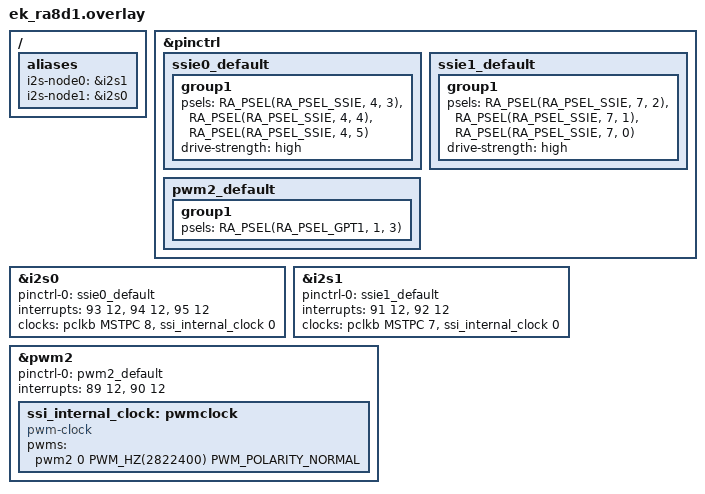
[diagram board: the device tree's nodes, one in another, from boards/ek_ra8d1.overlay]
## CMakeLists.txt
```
# SPDX-License-Identifier: Apache-2.0

cmake_minimum_required(VERSION 3.28.0)

find_package(Zephyr REQUIRED HINTS $ENV{ZEPHYR_BASE})
project(i2s_speed)

FILE(GLOB app_sources src/*.c)
target_sources(app PRIVATE ${app_sources})
```

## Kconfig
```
#
# Copyright (c) 2021, NXP
#
# SPDX-License-Identifier: Apache-2.0
#

mainmenu "I2S Speed Test"

source "Kconfig.zephyr"

config I2S_TEST_SEPARATE_DEVICES
	bool "Use two separate I2S ports for loopback"
	help
	  Use separate I2S ports for transmit and receive.

config I2S_TEST_USE_I2S_DIR_BOTH
	bool "Use I2S_DIR_BOTH value to perform RX/TX transfers"
	default y if DT_HAS_NORDIC_NRF_I2S_ENABLED || DT_HAS_NORDIC_NRF_TDM_ENABLED
	help
	  Use the I2S_DIR_BOTH enumeration value to trigger commands in test
	  cases involving both reception and transmission. Use of this option
	  is essential for devices that cannot independently start and stop
	  the RX and TX streams.

config I2S_TEST_USE_GPIO_LOOPBACK
	bool "Use GPIO loopback"
	default y if DT_HAS_NORDIC_NRF_I2S_ENABLED || DT_HAS_NORDIC_NRF_TDM_ENABLED
	help
	  Use wiring between the data-out and data-in pins for looping back
	  data. This option is intended to be used for devices that do not
	  provide the internal loopback functionality.

config I2S_TEST_ALLOWED_DATA_OFFSET
	int "Allowed offset in received data"
	default 2 if DT_HAS_NORDIC_NRF_I2S_ENABLED || DT_HAS_NORDIC_NRF_TDM_ENABLED
	default 0
	help
	  Maximum allowed offset between sent and received samples. Non-zero
	  value of this option may be needed when GPIO loopback is used.

config I2S_TEST_ALLOW_VARIABLE_OFFSET
	bool "Recalculate the data offset on every block read"
	help
	  If the data offset is not consistent between reads because of
	  timing variations in the hardware, enable this option to
	  always recalculate the offset.

config I2S_TEST_USE_32_SAMPLES_PER_BLOCK
	bool "Use 32 samples per block"
	help
	  When set to 'y', the test will use 32 samples per block
	  instead of the default 64 samples per block. This option
	  may be needed for devices with smaller hardware FIFOs.

config I2S_TEST_SKIP_SAMPLERATE_8000
	bool "Skip short transfer tests at 8000 samples per second"
	help
	  When set to 'y', short transfer tests at 8000 samples per second
	  will be skipped.

config I2S_TEST_SKIP_SAMPLERATE_16000
	bool "Skip short transfer tests at 16000 samples per second"
	help
	  When set to 'y', short transfer tests at 16000 samples per second
	  will be skipped.

config I2S_TEST_SKIP_SAMPLERATE_32000
	bool "Skip short transfer tests at 32000 samples per second"
	help
	  When set to 'y', short transfer tests at 32000 samples per second
	  will be skipped.

config I2S_TEST_SKIP_SAMPLERATE_44100
	bool "Skip short transfer tests at 44100 samples per second"
	help
	  When set to 'y', short transfer tests at 44100 samples per second
	  will be skipped.

config I2S_TEST_SKIP_SAMPLERATE_48000
	bool "Skip short transfer tests at 48000 samples per second"
	help
	  When set to 'y', short transfer tests at 48000 samples per second
	  will be skipped.

config I2S_TEST_SKIP_SAMPLERATE_88200
	bool "Skip short transfer tests at 88200 samples per second"
	help
	  When set to 'y', short transfer tests at 88200 samples per second
	  will be skipped.

config I2S_TEST_SKIP_SAMPLERATE_96000
	bool "Skip short transfer tests at 96000 samples per second"
	help
	  When set to 'y', short transfer tests at 96000 samples per second
	  will be skipped.
```

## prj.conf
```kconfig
CONFIG_I2S=y
CONFIG_ZTEST=y
```

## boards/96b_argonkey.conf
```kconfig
CONFIG_HEAP_MEM_POOL_SIZE=1024
```

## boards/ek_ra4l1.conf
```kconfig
#
# Copyright (c) 2025 Renesas Electronics Corporation
#
# SPDX-License-Identifier: Apache-2.0
#

CONFIG_PWM=y
CONFIG_CLOCK_CONTROL=y
CONFIG_I2S_INIT_PRIORITY=52
CONFIG_I2S_TEST_USE_GPIO_LOOPBACK=y
CONFIG_I2S_TEST_USE_I2S_DIR_BOTH=y
CONFIG_CLOCK_CONTROL_FIXED_RATE_CLOCK=y
CONFIG_I2S_TEST_SKIP_SAMPLERATE_8000=y
CONFIG_I2S_TEST_SKIP_SAMPLERATE_16000=y
CONFIG_I2S_TEST_SKIP_SAMPLERATE_32000=y
CONFIG_I2S_TEST_SKIP_SAMPLERATE_48000=y
CONFIG_I2S_TEST_SKIP_SAMPLERATE_96000=y
```

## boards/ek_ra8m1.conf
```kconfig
#
# Copyright (c) 2025 Renesas Electronics Corporation
#
# SPDX-License-Identifier: Apache-2.0
#

CONFIG_PWM=y
CONFIG_CLOCK_CONTROL=y
CONFIG_I2S_INIT_PRIORITY=52
CONFIG_I2S_TEST_USE_GPIO_LOOPBACK=y
CONFIG_I2S_TEST_SEPARATE_DEVICES=y
CONFIG_CLOCK_CONTROL_FIXED_RATE_CLOCK=y
CONFIG_I2S_TEST_SKIP_SAMPLERATE_8000=y
CONFIG_I2S_TEST_SKIP_SAMPLERATE_16000=y
CONFIG_I2S_TEST_SKIP_SAMPLERATE_32000=y
CONFIG_I2S_TEST_SKIP_SAMPLERATE_48000=y
CONFIG_I2S_TEST_SKIP_SAMPLERATE_96000=y
```

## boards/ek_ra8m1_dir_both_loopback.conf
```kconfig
# Copyright (c) 2025 Renesas Electronics Corporation
# SPDX-License-Identifier: Apache-2.0

CONFIG_I2S_INIT_PRIORITY=52
CONFIG_I2S_TEST_USE_GPIO_LOOPBACK=y
CONFIG_I2S_TEST_USE_I2S_DIR_BOTH=y
CONFIG_I2S_TEST_SKIP_SAMPLERATE_8000=y
CONFIG_I2S_TEST_SKIP_SAMPLERATE_16000=y
CONFIG_I2S_TEST_SKIP_SAMPLERATE_32000=y
CONFIG_I2S_TEST_SKIP_SAMPLERATE_48000=y
CONFIG_I2S_TEST_SKIP_SAMPLERATE_96000=y
```

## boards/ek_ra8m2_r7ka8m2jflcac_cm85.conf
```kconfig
# Copyright (c) 2025 Renesas Electronics Corporation
# SPDX-License-Identifier: Apache-2.0

CONFIG_I2S_INIT_PRIORITY=52
CONFIG_I2S_TEST_USE_GPIO_LOOPBACK=y
CONFIG_I2S_TEST_SEPARATE_DEVICES=y
CONFIG_I2S_TEST_SKIP_SAMPLERATE_8000=y
CONFIG_I2S_TEST_SKIP_SAMPLERATE_16000=y
CONFIG_I2S_TEST_SKIP_SAMPLERATE_32000=y
CONFIG_I2S_TEST_SKIP_SAMPLERATE_48000=y
CONFIG_I2S_TEST_SKIP_SAMPLERATE_96000=y
```

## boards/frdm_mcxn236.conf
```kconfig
#
# Copyright (c) 2024, NXP
#
# SPDX-License-Identifier: Apache-2.0
#

# SAI peripheral does not have loopback mode.  Use 2 SAI peripherals connected
# together externally.
CONFIG_I2S_TEST_SEPARATE_DEVICES=y

# Repeat test continually to help find intermittent issues
CONFIG_ZTEST_RETEST_IF_PASSED=y

# I2S and DMA logging can occur in interrupt context, and interfere with I2S
# stream timing.  If using either logging, set logging to deferred
# CONFIG_LOG_MODE_DEFERRED=y

CONFIG_DMA_LOG_LEVEL_OFF=y
CONFIG_I2S_LOG_LEVEL_OFF=y
CONFIG_I2S_TEST_USE_GPIO_LOOPBACK=y
```

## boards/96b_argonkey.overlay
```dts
/* i2s-node0 is the transmitter/receiver */

/ {
	aliases {
		i2s-node0 = &i2s5;
	};
};
```

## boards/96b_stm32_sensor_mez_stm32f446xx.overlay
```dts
/* i2s-node0 is the transmitter/receiver */

/ {
	aliases {
		i2s-node0 = &i2s2;
	};
};
```

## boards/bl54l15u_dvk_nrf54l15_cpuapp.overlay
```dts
/*
 * Copyright (c) 2024 Nordic Semiconductor ASA
 * Copyright (c) 2025 Ezurio LLC
 *
 * SPDX-License-Identifier: Apache-2.0
 */

/* i2s-node0 is the transmitter/receiver */

/ {
	aliases {
		i2s-node0 = &i2s20;
	};
};

&pinctrl {
	i2s20_default_alt: i2s20_default_alt {
		group1 {
			psels = <NRF_PSEL(I2S_SCK_M, 1, 11)>,
				<NRF_PSEL(I2S_LRCK_M, 1, 12)>,
				<NRF_PSEL(I2S_SDOUT, 1, 8)>,
				<NRF_PSEL(I2S_SDIN, 1, 9)>;
		};
	};
};

&i2s20 {
	pinctrl-0 = <&i2s20_default_alt>;
	pinctrl-names = "default";
	status = "okay";
};
```

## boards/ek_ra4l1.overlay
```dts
/*
 * Copyright (c) 2025 Renesas Electronics Corporation
 *
 * SPDX-License-Identifier: Apache-2.0
 */

#include <zephyr/dt-bindings/pwm/pwm.h>

/ {
	aliases {
		i2s-node0 = &i2s0;
	};
};

&pinctrl {
	ssie0_default: ssie0_default {
		group1 {
			/* SSI_BCK SSI_LRCK SSI_TX SSI_RX */
			psels = <RA_PSEL(RA_PSEL_SSIE, 4, 3)>,
				<RA_PSEL(RA_PSEL_SSIE, 4, 4)>,
				<RA_PSEL(RA_PSEL_SSIE, 6, 8)>,
				<RA_PSEL(RA_PSEL_SSIE, 1, 15)>;
			drive-strength = "high";
		};
	};

	pwm2_default: pwm2_default {
		group1 {
			/* GTIOC2A */
			psels = <RA_PSEL(RA_PSEL_GPT1, 4, 7)>;
		};
	};
};

&i2s0 {
	pinctrl-0 = <&ssie0_default>;
	pinctrl-names = "default";
	interrupts = <61 12>, <62 12>, <63 12>;
	interrupt-names = "ssi_txi", "ssi_rxi", "ssi_if";
	clocks = <&pclkb MSTPC 8>, <&ssi_internal_clock 0>;
	clock-names = "pclk", "audio-clock";
	status = "okay";
};

&pwm2 {
	pinctrl-0 = <&pwm2_default>;
	pinctrl-names = "default";
	interrupts = <59 12>, <60 12>;
	interrupt-names = "gtioca", "overflow";
	status = "okay";

	ssi_internal_clock: pwmclock {
		compatible = "pwm-clock";
		#clock-cells = <1>;
		pwms = <&pwm2 0 PWM_HZ(2822400) PWM_POLARITY_NORMAL>;
		status = "okay";
	};
};
```

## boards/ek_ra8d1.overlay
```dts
/*
 * Copyright (c) 2025 Renesas Electronics Corporation
 *
 * SPDX-License-Identifier: Apache-2.0
 */

#include <zephyr/dt-bindings/pwm/pwm.h>

/ {
	aliases {
		i2s-node0 = &i2s1;
		i2s-node1 = &i2s0;
	};
};

&pinctrl {
	ssie0_default: ssie0_default {
		group1 {
			/* SSI_BCK SSI_LRCK SSI_TX */
			psels = <RA_PSEL(RA_PSEL_SSIE, 4, 3)>,
				<RA_PSEL(RA_PSEL_SSIE, 4, 4)>,
				<RA_PSEL(RA_PSEL_SSIE, 4, 5)>;
			drive-strength = "high";
		};
	};

	ssie1_default: ssie1_default {
		group1 {
			/* SSI_BCK SSI_LRCK SSI_DATA */
			psels = <RA_PSEL(RA_PSEL_SSIE, 7, 2)>,
				<RA_PSEL(RA_PSEL_SSIE, 7, 1)>,
				<RA_PSEL(RA_PSEL_SSIE, 7, 0)>;
			drive-strength = "high";
		};
	};

	pwm2_default: pwm2_default {
		group1 {
			/* GTIOC2A */
			psels = <RA_PSEL(RA_PSEL_GPT1, 1, 3)>;
		};
	};
};

&i2s0 {
	pinctrl-0 = <&ssie0_default>;
	pinctrl-names = "default";
	interrupts = <93 12>, <94 12>, <95 12>;
	interrupt-names = "ssi_txi", "ssi_rxi", "ssi_if";
	clocks = <&pclkb MSTPC 8>, <&ssi_internal_clock 0>;
	clock-names = "pclk", "audio-clock";
	status = "okay";
};

&i2s1 {
	pinctrl-0 = <&ssie1_default>;
	pinctrl-names = "default";
	interrupts = <91 12>, <92 12>;
	interrupt-names = "ssi_rt", "ssi_if";
	clocks = <&pclkb MSTPC 7>, <&ssi_internal_clock 0>;
	clock-names = "pclk", "audio-clock";
	status = "okay";
};

&pwm2 {
	pinctrl-0 = <&pwm2_default>;
	pinctrl-names = "default";
	interrupts = <89 12>, <90 12>;
	interrupt-names = "gtioca", "overflow";
	status = "okay";

	ssi_internal_clock: pwmclock {
		compatible = "pwm-clock";
		#clock-cells = <1>;
		pwms = <&pwm2 0 PWM_HZ(2822400) PWM_POLARITY_NORMAL>;
		status = "okay";
	};
};
```

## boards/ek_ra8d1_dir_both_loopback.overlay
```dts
/*
 * Copyright (c) 2025 Renesas Electronics Corporation
 *
 * SPDX-License-Identifier: Apache-2.0
 */

#include <zephyr/dt-bindings/pwm/pwm.h>

/ {
	aliases {
		i2s-node0 = &i2s0;
	};
};

&pinctrl {
	ssie0_default: ssie0_default {
		group1 {
			/* SSI_BCK SSI_LRCK SSI_TX SSI_RX */
			psels = <RA_PSEL(RA_PSEL_SSIE, 4, 3)>,
				<RA_PSEL(RA_PSEL_SSIE, 4, 4)>,
				<RA_PSEL(RA_PSEL_SSIE, 4, 5)>,
				<RA_PSEL(RA_PSEL_SSIE, 4, 6)>;
			drive-strength = "high";
		};
	};

	pwm2_default: pwm2_default {
		group1 {
			/* GTIOC2A */
			psels = <RA_PSEL(RA_PSEL_GPT1, 1, 3)>;
		};
	};
};

&i2s0 {
	pinctrl-0 = <&ssie0_default>;
	pinctrl-names = "default";
	interrupts = <93 12>, <94 12>, <95 12>;
	interrupt-names = "ssi_txi", "ssi_rxi", "ssi_if";
	clocks = <&pclkb MSTPC 8>, <&ssi_internal_clock 0>;
	clock-names = "pclk", "audio-clock";
	status = "okay";
};

&pwm2 {
	pinctrl-0 = <&pwm2_default>;
	pinctrl-names = "default";
	interrupts = <91 12>, <92 12>;
	interrupt-names = "gtioca", "overflow";
	status = "okay";

	ssi_internal_clock: pwmclock {
		compatible = "pwm-clock";
		#clock-cells = <1>;
		pwms = <&pwm2 0 PWM_HZ(2822400) PWM_POLARITY_NORMAL>;
		status = "okay";
	};
};
```

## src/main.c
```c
/*
 * Copyright (c) 2017 comsuisse AG
 *
 * SPDX-License-Identifier: Apache-2.0
 */


#include <zephyr/kernel.h>
#include <zephyr/ztest.h>

extern void *test_i2s_speed_configure(void);
extern void *test_i2s_speed_rxtx_configure(void);
ZTEST_SUITE(drivers_i2s_speed, NULL, test_i2s_speed_configure, NULL, NULL, NULL);
ZTEST_SUITE(drivers_i2s_speed_both_rxtx, NULL, test_i2s_speed_rxtx_configure, NULL, NULL, NULL);
```

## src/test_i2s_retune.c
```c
/*
 * Copyright 2026 NXP
 *
 * SPDX-License-Identifier: Apache-2.0
 */

#include <zephyr/kernel.h>
#include <zephyr/ztest.h>
#include <zephyr/drivers/i2s.h>
#include <zephyr/sys/iterable_sections.h>

#define DEV_NODE_RX DT_ALIAS(i2s_node0)
#ifdef CONFIG_I2S_TEST_SEPARATE_DEVICES
#define DEV_NODE_TX DT_ALIAS(i2s_node1)
#else
#define DEV_NODE_TX DEV_NODE_RX
#endif
#define BLOCK_SIZE (64 * 2 * sizeof(int16_t))
#define NUM_BLOCKS 8
#define TIMEOUT 2000

#if DT_NODE_HAS_COMPAT(DEV_NODE_RX, nxp_mcux_i2s) && \
	DT_NODE_HAS_COMPAT(DEV_NODE_TX, nxp_mcux_i2s) && !defined(CONFIG_I2S_HAS_PLL_SETTING)
#define RETUNE_TEST_SUPPORTED 1
#else
#define RETUNE_TEST_SUPPORTED 0
#endif

#ifdef CONFIG_NOCACHE_MEMORY
#define SLAB_ATTR __nocache
#else
#define SLAB_ATTR
#endif

static char SLAB_ATTR __aligned(WB_UP(32)) tx_buf[NUM_BLOCKS * WB_UP(BLOCK_SIZE)];
static char SLAB_ATTR __aligned(WB_UP(32)) rx_buf[(NUM_BLOCKS + 2) * WB_UP(BLOCK_SIZE)];
STRUCT_SECTION_ITERABLE(k_mem_slab, retune_tx_slab) =
	Z_MEM_SLAB_INITIALIZER(retune_tx_slab, tx_buf, WB_UP(BLOCK_SIZE), NUM_BLOCKS);
STRUCT_SECTION_ITERABLE(k_mem_slab, retune_rx_slab) =
	Z_MEM_SLAB_INITIALIZER(retune_rx_slab, rx_buf, WB_UP(BLOCK_SIZE), NUM_BLOCKS + 2);

static const struct device *dev_rx;
static const struct device *dev_tx;

static const struct device *device_for_dir(enum i2s_dir dir)
{
	return dir == I2S_DIR_TX ? dev_tx : dev_rx;
}

static int configure(enum i2s_dir dir, uint32_t rate)
{
	struct i2s_config cfg = {
		.word_size = 16,
		.channels = 2,
		.format = I2S_FMT_DATA_FORMAT_I2S,
		.frame_clk_freq = rate,
		.block_size = BLOCK_SIZE,
		.timeout = TIMEOUT,
		.options = I2S_OPT_LOOPBACK,
		.mem_slab = dir == I2S_DIR_TX ? &retune_tx_slab : &retune_rx_slab,
	};

	if (dir == I2S_DIR_TX) {
		cfg.options |= I2S_OPT_FRAME_CLK_CONTROLLER | I2S_OPT_BIT_CLK_CONTROLLER;
	} else {
		cfg.options |= I2S_OPT_FRAME_CLK_TARGET | I2S_OPT_BIT_CLK_TARGET;
	}

	return i2s_configure(device_for_dir(dir), dir, &cfg);
}

static void reset_stream(enum i2s_dir dir)
{
	struct i2s_config cfg = {0};

	const struct device *dev = device_for_dir(dir);

	(void)i2s_trigger(dev, dir, I2S_TRIGGER_DROP);
	(void)i2s_configure(dev, dir, &cfg);
}

static void reset_all(void)
{
	reset_stream(I2S_DIR_TX);
	reset_stream(I2S_DIR_RX);
}

static void *setup(void)
{
	dev_rx = DEVICE_DT_GET_OR_NULL(DEV_NODE_RX);
	dev_tx = DEVICE_DT_GET_OR_NULL(DEV_NODE_TX);
	zassert_not_null(dev_rx);
	zassert_not_null(dev_tx);
	zassert_true(device_is_ready(dev_rx));
	zassert_true(device_is_ready(dev_tx));
	return NULL;
}

static void before(void *fixture)
{
	ARG_UNUSED(fixture);
	if (!RETUNE_TEST_SUPPORTED) {
		ztest_test_skip();
	}
	reset_all();
}

static void after(void *fixture)
{
	ARG_UNUSED(fixture);
	reset_all();
}

ZTEST(retune, test_idle_peer_is_invalidated_and_purged)
{
	void *block;
	uint32_t free_before;
	int ret;

	zassert_ok(configure(I2S_DIR_TX, 48000));
	free_before = k_mem_slab_num_free_get(&retune_tx_slab);

	for (int i = 0; i < 2; i++) {
		zassert_ok(k_mem_slab_alloc(&retune_tx_slab, &block, K_NO_WAIT));
		zassert_ok(i2s_write(dev_tx, block, BLOCK_SIZE));
	}

	ret = configure(I2S_DIR_RX, 44100);
	zassert_ok(ret, "idle peer retune failed: %d", ret);
	zassert_equal(k_mem_slab_num_free_get(&retune_tx_slab), free_before,
		      "invalidated peer buffers were not purged");
	zassert_equal(i2s_trigger(dev_tx, I2S_DIR_TX, I2S_TRIGGER_START), -EIO);
}

ZTEST(retune, test_running_peer_retune_is_rejected)
{
	void *block;
	int ret;

	zassert_ok(configure(I2S_DIR_TX, 48000));
	zassert_ok(k_mem_slab_alloc(&retune_tx_slab, &block, K_NO_WAIT));
	zassert_ok(i2s_write(dev_tx, block, BLOCK_SIZE));
	zassert_ok(i2s_trigger(dev_tx, I2S_DIR_TX, I2S_TRIGGER_START));

	ret = configure(I2S_DIR_RX, 44100);
	zassert_equal(ret, -EINVAL, "running peer retune returned %d", ret);
}

ZTEST_SUITE(retune, NULL, setup, before, after, NULL);
```

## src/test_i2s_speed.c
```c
/*
 * Copyright (c) 2017 comsuisse AG
 *
 * SPDX-License-Identifier: Apache-2.0
 */


#include <zephyr/kernel.h>
#include <zephyr/ztest.h>
#include <zephyr/drivers/i2s.h>
#include <zephyr/sys/iterable_sections.h>

#define I2S_DEV_NODE_RX DT_ALIAS(i2s_node0)
#ifdef CONFIG_I2S_TEST_SEPARATE_DEVICES
#define I2S_DEV_NODE_TX DT_ALIAS(i2s_node1)
#else
#define I2S_DEV_NODE_TX DT_ALIAS(i2s_node0)
#endif

#define NUM_BLOCKS 20
#if (CONFIG_I2S_TEST_USE_32_SAMPLES_PER_BLOCK)
#define SAMPLE_NO 32
#else
#define SAMPLE_NO 64
#endif

/* The data_l represent a sine wave */
static int16_t data_l[SAMPLE_NO] = {
	  3211,   6392,   9511,  12539,  15446,  18204,  20787,  23169,
	 25329,  27244,  28897,  30272,  31356,  32137,  32609,  32767,
	 32609,  32137,  31356,  30272,  28897,  27244,  25329,  23169,
	 20787,  18204,  15446,  12539,   9511,   6392,   3211,      0,
#if (!CONFIG_I2S_TEST_USE_32_SAMPLES_PER_BLOCK)
	 -3212,  -6393,  -9512, -12540, -15447, -18205, -20788, -23170,
	-25330, -27245, -28898, -30273, -31357, -32138, -32610, -32767,
	-32610, -32138, -31357, -30273, -28898, -27245, -25330, -23170,
	-20788, -18205, -15447, -12540,  -9512,  -6393,  -3212,     -1,
#endif
};

/* The data_r represent a sine wave shifted by 90 deg to data_l sine wave */
static int16_t data_r[SAMPLE_NO] = {
	 32609,  32137,  31356,  30272,  28897,  27244,  25329,  23169,
	 20787,  18204,  15446,  12539,   9511,   6392,   3211,      0,
	 -3212,  -6393,  -9512, -12540, -15447, -18205, -20788, -23170,
	-25330, -27245, -28898, -30273, -31357, -32138, -32610, -32767,
#if (!CONFIG_I2S_TEST_USE_32_SAMPLES_PER_BLOCK)
	-32610, -32138, -31357, -30273, -28898, -27245, -25330, -23170,
	-20788, -18205, -15447, -12540,  -9512,  -6393,  -3212,     -1,
	  3211,   6392,   9511,  12539,  15446,  18204,  20787,  23169,
	 25329,  27244,  28897,  30272,  31356,  32137,  32609,  32767,
#endif
};

#define BLOCK_SIZE (2 * sizeof(data_l))

#ifdef CONFIG_NOCACHE_MEMORY
	#define MEM_SLAB_CACHE_ATTR __nocache
#else
	#define MEM_SLAB_CACHE_ATTR
#endif /* CONFIG_NOCACHE_MEMORY */

/*
 * NUM_BLOCKS is the number of blocks used by the test. Some of the drivers,
 * e.g. i2s_mcux_flexcomm, permanently keep ownership of a few RX buffers. Add a few more
 * RX blocks to satisfy this requirement
 */

char MEM_SLAB_CACHE_ATTR __aligned(WB_UP(32))
	_k_mem_slab_buf_rx_0_mem_slab[(NUM_BLOCKS + 2) * WB_UP(BLOCK_SIZE)];
STRUCT_SECTION_ITERABLE(k_mem_slab, rx_0_mem_slab) =
	Z_MEM_SLAB_INITIALIZER(rx_0_mem_slab, _k_mem_slab_buf_rx_0_mem_slab,
				WB_UP(BLOCK_SIZE), NUM_BLOCKS + 2);

char MEM_SLAB_CACHE_ATTR __aligned(WB_UP(32))
	_k_mem_slab_buf_tx_0_mem_slab[(NUM_BLOCKS) * WB_UP(BLOCK_SIZE)];
STRUCT_SECTION_ITERABLE(k_mem_slab, tx_0_mem_slab) =
	Z_MEM_SLAB_INITIALIZER(tx_0_mem_slab, _k_mem_slab_buf_tx_0_mem_slab,
				WB_UP(BLOCK_SIZE), NUM_BLOCKS);

static const struct device *dev_i2s_rx;
static const struct device *dev_i2s_tx;
static const struct device *dev_i2s_rxtx;
static bool dir_both_supported;

static void fill_buf(int16_t *tx_block, int att)
{
	for (int i = 0; i < SAMPLE_NO; i++) {
		tx_block[2 * i] = data_l[i] >> att;
		tx_block[2 * i + 1] = data_r[i] >> att;
	}
}

static int verify_buf(int16_t *rx_block, int att)
{
	int sample_no = SAMPLE_NO;

#if (CONFIG_I2S_TEST_ALLOWED_DATA_OFFSET > 0)
#if (CONFIG_I2S_TEST_ALLOW_VARIABLE_OFFSET)
	int offset = -1;
#else
	static ZTEST_DMEM int offset = -1;
#endif

	if (offset < 0) {
		do {
			++offset;
			if (offset > CONFIG_I2S_TEST_ALLOWED_DATA_OFFSET) {
				TC_PRINT("Allowed data offset exceeded\n");
				return -TC_FAIL;
			}
		} while (rx_block[2 * offset] != data_l[0] >> att);

#if (!CONFIG_I2S_TEST_ALLOW_VARIABLE_OFFSET)
		TC_PRINT("Using data offset: %d\n", offset);
#endif
	}

	rx_block += 2 * offset;
	sample_no -= offset;
#endif

	for (int i = 0; i < sample_no; i++) {
		if (rx_block[2 * i] != data_l[i] >> att) {
			TC_PRINT("Error: att %d: data_l mismatch at position "
				 "%d, expected %d, actual %d\n",
				 att, i, data_l[i] >> att, rx_block[2 * i]);
			return -TC_FAIL;
		}
		if (rx_block[2 * i + 1] != data_r[i] >> att) {
			TC_PRINT("Error: att %d: data_r mismatch at position "
				 "%d, expected %d, actual %d\n",
				 att, i, data_r[i] >> att, rx_block[2 * i + 1]);
			return -TC_FAIL;
		}
	}

	return TC_PASS;
}

#define TIMEOUT          2000

static int configure_stream(const struct device *dev_i2s, enum i2s_dir dir, uint32_t frame_clk_freq)
{
	int ret;
	struct i2s_config i2s_cfg = {0};

	i2s_cfg.word_size = 16U;
	i2s_cfg.channels = 2U;
	i2s_cfg.format = I2S_FMT_DATA_FORMAT_I2S;
	i2s_cfg.frame_clk_freq = frame_clk_freq;
	i2s_cfg.block_size = BLOCK_SIZE;
	i2s_cfg.timeout = TIMEOUT;

	if (dir == I2S_DIR_TX) {
		/* Configure the Transmit port as Controller */
		i2s_cfg.options = I2S_OPT_FRAME_CLK_CONTROLLER
				| I2S_OPT_BIT_CLK_CONTROLLER;
	} else if (dir == I2S_DIR_RX) {
		/* Configure the Receive port as Target */
		i2s_cfg.options = I2S_OPT_FRAME_CLK_TARGET
				| I2S_OPT_BIT_CLK_TARGET;
	} else { /* dir == I2S_DIR_BOTH */
		i2s_cfg.options = I2S_OPT_FRAME_CLK_CONTROLLER
				| I2S_OPT_BIT_CLK_CONTROLLER;
	}

	if (!IS_ENABLED(CONFIG_I2S_TEST_USE_GPIO_LOOPBACK)) {
		i2s_cfg.options |= I2S_OPT_LOOPBACK;
	}

	if (dir == I2S_DIR_TX || dir == I2S_DIR_BOTH) {
		i2s_cfg.mem_slab = &tx_0_mem_slab;
		ret = i2s_configure(dev_i2s, I2S_DIR_TX, &i2s_cfg);
		if (ret < 0) {
			TC_PRINT("Failed to configure I2S TX stream (%d)\n",
				 ret);
			return -TC_FAIL;
		}
	}

	if (dir == I2S_DIR_RX || dir == I2S_DIR_BOTH) {
		i2s_cfg.mem_slab = &rx_0_mem_slab;
		ret = i2s_configure(dev_i2s, I2S_DIR_RX, &i2s_cfg);
		if (ret < 0) {
			TC_PRINT("Failed to configure I2S RX stream (%d)\n",
				 ret);
			return -TC_FAIL;
		}
	}

	return TC_PASS;
}

static void i2s_transfer_short(uint32_t frame_clk_freq)
{
	if (IS_ENABLED(CONFIG_I2S_TEST_USE_I2S_DIR_BOTH)) {
		TC_PRINT("RX/TX transfer requires use of I2S_DIR_BOTH.\n");
		ztest_test_skip();
		return;
	}

	void *rx_block[3];
	void *tx_block;
	size_t rx_size;
	int ret;

	/* Configure I2S TX and I2S RX transfer. */
	ret = configure_stream(dev_i2s_tx, I2S_DIR_TX, frame_clk_freq);
	zassert_equal(ret, TC_PASS);
	ret = configure_stream(dev_i2s_rx, I2S_DIR_RX, frame_clk_freq);
	zassert_equal(ret, TC_PASS);

	/* Prefill TX queue */
	for (int i = 0; i < 3; i++) {
		ret = k_mem_slab_alloc(&tx_0_mem_slab, &tx_block, K_FOREVER);
		zassert_equal(ret, 0);
		fill_buf((uint16_t *)tx_block, i);

		ret = i2s_write(dev_i2s_tx, tx_block, BLOCK_SIZE);
		zassert_equal(ret, 0);

		TC_PRINT("%d->OK\n", i);
	}

	/* Start reception */
	ret = i2s_trigger(dev_i2s_rx, I2S_DIR_RX, I2S_TRIGGER_START);
	zassert_equal(ret, 0, "RX START trigger failed");

	/* Start transmission */
	ret = i2s_trigger(dev_i2s_tx, I2S_DIR_TX, I2S_TRIGGER_START);
	zassert_equal(ret, 0, "TX START trigger failed");

	/* All data written, drain TX queue and stop the transmission */
	ret = i2s_trigger(dev_i2s_tx, I2S_DIR_TX, I2S_TRIGGER_DRAIN);
	zassert_equal(ret, 0, "TX DRAIN trigger failed");

	ret = i2s_read(dev_i2s_rx, &rx_block[0], &rx_size);
	zassert_equal(ret, 0);
	zassert_equal(rx_size, BLOCK_SIZE);

	ret = i2s_read(dev_i2s_rx, &rx_block[1], &rx_size);
	zassert_equal(ret, 0);
	zassert_equal(rx_size, BLOCK_SIZE);

	/* All but one data block read, stop reception */
	ret = i2s_trigger(dev_i2s_rx, I2S_DIR_RX, I2S_TRIGGER_STOP);
	zassert_equal(ret, 0, "RX STOP trigger failed");

	ret = i2s_read(dev_i2s_rx, &rx_block[2], &rx_size);
	zassert_equal(ret, 0);
	zassert_equal(rx_size, BLOCK_SIZE);

	/* Verify received data */
	ret = verify_buf((uint16_t *)rx_block[0], 0);
	zassert_equal(ret, 0);
	k_mem_slab_free(&rx_0_mem_slab, rx_block[0]);
	TC_PRINT("%d<-OK\n", 1);

	ret = verify_buf((uint16_t *)rx_block[1], 1);
	zassert_equal(ret, 0);
	k_mem_slab_free(&rx_0_mem_slab, rx_block[1]);
	TC_PRINT("%d<-OK\n", 2);

	ret = verify_buf((uint16_t *)rx_block[2], 2);
	zassert_equal(ret, 0);
	k_mem_slab_free(&rx_0_mem_slab, rx_block[2]);
	TC_PRINT("%d<-OK\n", 3);
}

/** @brief Short I2S transfer at 8000 samples per second.
 *
 * - TX stream START trigger starts transmission.
 * - RX stream START trigger starts reception.
 * - sending / receiving a short sequence of data returns success.
 * - TX stream DRAIN trigger empties the transmit queue.
 * - RX stream STOP trigger stops reception.
 */
ZTEST(drivers_i2s_speed, test_i2s_transfer_short_08000)
{
	Z_TEST_SKIP_IFDEF(CONFIG_I2S_TEST_SKIP_SAMPLERATE_8000);

	i2s_transfer_short(8000);
}

/** @brief Short I2S transfer at 16000 samples per second.
 *
 * - TX stream START trigger starts transmission.
 * - RX stream START trigger starts reception.
 * - sending / receiving a short sequence of data returns success.
 * - TX stream DRAIN trigger empties the transmit queue.
 * - RX stream STOP trigger stops reception.
 */
ZTEST(drivers_i2s_speed, test_i2s_transfer_short_16000)
{
	Z_TEST_SKIP_IFDEF(CONFIG_I2S_TEST_SKIP_SAMPLERATE_16000);

	i2s_transfer_short(16000);
}

/** @brief Short I2S transfer at 32000 samples per second.
 *
 * - TX stream START trigger starts transmission.
 * - RX stream START trigger starts reception.
 * - sending / receiving a short sequence of data returns success.
 * - TX stream DRAIN trigger empties the transmit queue.
 * - RX stream STOP trigger stops reception.
 */
ZTEST(drivers_i2s_speed, test_i2s_transfer_short_32000)
{
	Z_TEST_SKIP_IFDEF(CONFIG_I2S_TEST_SKIP_SAMPLERATE_32000);

	i2s_transfer_short(32000);
}

/** @brief Short I2S transfer at 44100 samples per second.
 *
 * - TX stream START trigger starts transmission.
 * - RX stream START trigger starts reception.
 * - sending / receiving a short sequence of data returns success.
 * - TX stream DRAIN trigger empties the transmit queue.
 * - RX stream STOP trigger stops reception.
 */
ZTEST(drivers_i2s_speed, test_i2s_transfer_short_44100)
{
	Z_TEST_SKIP_IFDEF(CONFIG_I2S_TEST_SKIP_SAMPLERATE_44100);

	i2s_transfer_short(44100);
}

/** @brief Short I2S transfer at 48000 samples per second.
 *
 * - TX stream START trigger starts transmission.
 * - RX stream START trigger starts reception.
 * - sending / receiving a short sequence of data returns success.
 * - TX stream DRAIN trigger empties the transmit queue.
 * - RX stream STOP trigger stops reception.
 */
ZTEST(drivers_i2s_speed, test_i2s_transfer_short_48000)
{
	Z_TEST_SKIP_IFDEF(CONFIG_I2S_TEST_SKIP_SAMPLERATE_48000);

	i2s_transfer_short(48000);
}

/** @brief Short I2S transfer at 88200 samples per second.
 *
 * - TX stream START trigger starts transmission.
 * - RX stream START trigger starts reception.
 * - sending / receiving a short sequence of data returns success.
 * - TX stream DRAIN trigger empties the transmit queue.
 * - RX stream STOP trigger stops reception.
 */
ZTEST(drivers_i2s_speed, test_i2s_transfer_short_88200)
{
	Z_TEST_SKIP_IFDEF(CONFIG_I2S_TEST_SKIP_SAMPLERATE_88200);

	i2s_transfer_short(88200);
}

/** @brief Short I2S transfer at 96000 samples per second.
 *
 * - TX stream START trigger starts transmission.
 * - RX stream START trigger starts reception.
 * - sending / receiving a short sequence of data returns success.
 * - TX stream DRAIN trigger empties the transmit queue.
 * - RX stream STOP trigger stops reception.
 */
ZTEST(drivers_i2s_speed, test_i2s_transfer_short_96000)
{
	Z_TEST_SKIP_IFDEF(CONFIG_I2S_TEST_SKIP_SAMPLERATE_96000);

	i2s_transfer_short(96000);
}

/** @brief Long I2S transfer.
 *
 * - TX stream START trigger starts transmission.
 * - RX stream START trigger starts reception.
 * - sending / receiving a long sequence of data returns success.
 * - TX stream DRAIN trigger empties the transmit queue.
 * - RX stream STOP trigger stops reception.
 */
ZTEST(drivers_i2s_speed, test_i2s_transfer_long_44100)
{
	if (IS_ENABLED(CONFIG_I2S_TEST_USE_I2S_DIR_BOTH)) {
		TC_PRINT("RX/TX transfer requires use of I2S_DIR_BOTH.\n");
		ztest_test_skip();
		return;
	}

	void *rx_block[NUM_BLOCKS];
	void *tx_block[NUM_BLOCKS];
	size_t rx_size;
	int tx_idx;
	int rx_idx = 0;
	int num_verified;
	int ret;
	uint32_t frame_clk_freq = 44100;

	/* Configure I2S TX and I2S RX transfer. */
	ret = configure_stream(dev_i2s_tx, I2S_DIR_TX, frame_clk_freq);
	zassert_equal(ret, TC_PASS);
	ret = configure_stream(dev_i2s_rx, I2S_DIR_RX, frame_clk_freq);
	zassert_equal(ret, TC_PASS);

	/* Prepare TX data blocks */
	for (tx_idx = 0; tx_idx < NUM_BLOCKS; tx_idx++) {
		ret = k_mem_slab_alloc(&tx_0_mem_slab, &tx_block[tx_idx],
				       K_FOREVER);
		zassert_equal(ret, 0);
		fill_buf((uint16_t *)tx_block[tx_idx], tx_idx % 3);
	}

	tx_idx = 0;

	/* Prefill TX queue */
	ret = i2s_write(dev_i2s_tx, tx_block[tx_idx++], BLOCK_SIZE);
	zassert_equal(ret, 0);

	ret = i2s_write(dev_i2s_tx, tx_block[tx_idx++], BLOCK_SIZE);
	zassert_equal(ret, 0);

	/* Start reception */
	ret = i2s_trigger(dev_i2s_rx, I2S_DIR_RX, I2S_TRIGGER_START);
	zassert_equal(ret, 0, "RX START trigger failed");

	/* Start transmission */
	ret = i2s_trigger(dev_i2s_tx, I2S_DIR_TX, I2S_TRIGGER_START);
	zassert_equal(ret, 0, "TX START trigger failed");

	for (; tx_idx < NUM_BLOCKS; ) {
		ret = i2s_write(dev_i2s_tx, tx_block[tx_idx++], BLOCK_SIZE);
		zassert_equal(ret, 0);

		ret = i2s_read(dev_i2s_rx, &rx_block[rx_idx++], &rx_size);
		zassert_equal(ret, 0);
		zassert_equal(rx_size, BLOCK_SIZE);
	}

	/* All data written, flush TX queue and stop the transmission */
	ret = i2s_trigger(dev_i2s_tx, I2S_DIR_TX, I2S_TRIGGER_DRAIN);
	zassert_equal(ret, 0, "TX DRAIN trigger failed");

	ret = i2s_read(dev_i2s_rx, &rx_block[rx_idx++], &rx_size);
	zassert_equal(ret, 0);
	zassert_equal(rx_size, BLOCK_SIZE);

	/* All but one data block read, stop reception */
	ret = i2s_trigger(dev_i2s_rx, I2S_DIR_RX, I2S_TRIGGER_STOP);
	zassert_equal(ret, 0, "RX STOP trigger failed");

	ret = i2s_read(dev_i2s_rx, &rx_block[rx_idx++], &rx_size);
	zassert_equal(ret, 0);
	zassert_equal(rx_size, BLOCK_SIZE);

	TC_PRINT("%d TX blocks sent\n", tx_idx);
	TC_PRINT("%d RX blocks received\n", rx_idx);

	/* Verify received data */
	num_verified = 0;
	for (rx_idx = 0; rx_idx < NUM_BLOCKS; rx_idx++) {
		ret = verify_buf((uint16_t *)rx_block[rx_idx], rx_idx % 3);
		if (ret != 0) {
			TC_PRINT("%d RX block invalid\n", rx_idx);
		} else {
			num_verified++;
		}
		k_mem_slab_free(&rx_0_mem_slab, rx_block[rx_idx]);
	}
	zassert_equal(num_verified, NUM_BLOCKS, "Invalid RX blocks received");
}

static void i2s_dir_both_transfer_short(uint32_t frame_clk_freq)
{
	if (!dir_both_supported) {
		TC_PRINT("I2S_DIR_BOTH value is not supported.\n");
		ztest_test_skip();
		return;
	}

	void *rx_block[3];
	void *tx_block;
	size_t rx_size;
	int ret;

	/* Configure I2S Dir Both transfer. */
	ret = configure_stream(dev_i2s_rxtx, I2S_DIR_BOTH, frame_clk_freq);
	zassert_equal(ret, TC_PASS);

	/* Prefill TX queue */
	for (int i = 0; i < 3; i++) {
		ret = k_mem_slab_alloc(&tx_0_mem_slab, &tx_block, K_FOREVER);
		zassert_equal(ret, 0);
		fill_buf((uint16_t *)tx_block, i);

		ret = i2s_write(dev_i2s_rxtx, tx_block, BLOCK_SIZE);
		zassert_equal(ret, 0);

		TC_PRINT("%d->OK\n", i);
	}

	ret = i2s_trigger(dev_i2s_rxtx, I2S_DIR_BOTH, I2S_TRIGGER_START);
	zassert_equal(ret, 0, "RX/TX START trigger failed\n");

#ifdef CONFIG_I2S_TI_CC27XX
	/* CC27XX: Read at least 1 buffer before DRAIN to ensure synchronization.
	 * DRAIN stops RX after current block, not after all queued TX blocks.
	 */
	ret = i2s_read(dev_i2s_rxtx, &rx_block[0], &rx_size);
	zassert_equal(ret, 0);
	zassert_equal(rx_size, BLOCK_SIZE);
#endif

	/* All data written, drain TX queue and stop both streams. */
	ret = i2s_trigger(dev_i2s_rxtx, I2S_DIR_BOTH, I2S_TRIGGER_DRAIN);
	zassert_equal(ret, 0, "RX/TX DRAIN trigger failed");

#ifndef CONFIG_I2S_TI_CC27XX
	ret = i2s_read(dev_i2s_rxtx, &rx_block[0], &rx_size);
	zassert_equal(ret, 0);
	zassert_equal(rx_size, BLOCK_SIZE);
#endif

	ret = i2s_read(dev_i2s_rxtx, &rx_block[1], &rx_size);
	zassert_equal(ret, 0);
	zassert_equal(rx_size, BLOCK_SIZE);

	ret = i2s_read(dev_i2s_rxtx, &rx_block[2], &rx_size);
	zassert_equal(ret, 0);
	zassert_equal(rx_size, BLOCK_SIZE);

	/* Verify received data */
	ret = verify_buf((uint16_t *)rx_block[0], 0);
	zassert_equal(ret, 0);
	k_mem_slab_free(&rx_0_mem_slab, rx_block[0]);
	TC_PRINT("%d<-OK\n", 1);

	ret = verify_buf((uint16_t *)rx_block[1], 1);
	zassert_equal(ret, 0);
	k_mem_slab_free(&rx_0_mem_slab, rx_block[1]);
	TC_PRINT("%d<-OK\n", 2);

	ret = verify_buf((uint16_t *)rx_block[2], 2);
	zassert_equal(ret, 0);
	k_mem_slab_free(&rx_0_mem_slab, rx_block[2]);
	TC_PRINT("%d<-OK\n", 3);
}

/** @brief Short I2S transfer using I2S_DIR_BOTH and sample rate of 8000.
 *
 * - START trigger starts both the transmission and reception.
 * - Sending / receiving a short sequence of data returns success.
 * - DRAIN trigger empties the transmit queue and stops both streams.
 */
ZTEST(drivers_i2s_speed_both_rxtx, test_i2s_dir_both_transfer_short_08000)
{
	Z_TEST_SKIP_IFDEF(CONFIG_I2S_TEST_SKIP_SAMPLERATE_8000);

	i2s_dir_both_transfer_short(8000);
}

/** @brief Short I2S transfer using I2S_DIR_BOTH and sample rate of 16000.
 *
 * - START trigger starts both the transmission and reception.
 * - Sending / receiving a short sequence of data returns success.
 * - DRAIN trigger empties the transmit queue and stops both streams.
 */
ZTEST(drivers_i2s_speed_both_rxtx, test_i2s_dir_both_transfer_short_16000)
{
	Z_TEST_SKIP_IFDEF(CONFIG_I2S_TEST_SKIP_SAMPLERATE_16000);

	i2s_dir_both_transfer_short(16000);
}

/** @brief Short I2S transfer using I2S_DIR_BOTH and sample rate of 32000.
 *
 * - START trigger starts both the transmission and reception.
 * - Sending / receiving a short sequence of data returns success.
 * - DRAIN trigger empties the transmit queue and stops both streams.
 */
ZTEST(drivers_i2s_speed_both_rxtx, test_i2s_dir_both_transfer_short_32000)
{
	Z_TEST_SKIP_IFDEF(CONFIG_I2S_TEST_SKIP_SAMPLERATE_32000);

	i2s_dir_both_transfer_short(32000);
}

/** @brief Short I2S transfer using I2S_DIR_BOTH and sample rate of 44100.
 *
 * - START trigger starts both the transmission and reception.
 * - Sending / receiving a short sequence of data returns success.
 * - DRAIN trigger empties the transmit queue and stops both streams.
 */
ZTEST(drivers_i2s_speed_both_rxtx, test_i2s_dir_both_transfer_short_44100)
{
	Z_TEST_SKIP_IFDEF(CONFIG_I2S_TEST_SKIP_SAMPLERATE_44100);

	i2s_dir_both_transfer_short(44100);
}

/** @brief Short I2S transfer using I2S_DIR_BOTH and sample rate of 48000.
 *
 * - START trigger starts both the transmission and reception.
 * - Sending / receiving a short sequence of data returns success.
 * - DRAIN trigger empties the transmit queue and stops both streams.
 */
ZTEST(drivers_i2s_speed_both_rxtx, test_i2s_dir_both_transfer_short_48000)
{
	Z_TEST_SKIP_IFDEF(CONFIG_I2S_TEST_SKIP_SAMPLERATE_48000);

	i2s_dir_both_transfer_short(48000);
}

/** @brief Short I2S transfer using I2S_DIR_BOTH and sample rate of 88200.
 *
 * - START trigger starts both the transmission and reception.
 * - Sending / receiving a short sequence of data returns success.
 * - DRAIN trigger empties the transmit queue and stops both streams.
 */
ZTEST(drivers_i2s_speed_both_rxtx, test_i2s_dir_both_transfer_short_88200)
{
	Z_TEST_SKIP_IFDEF(CONFIG_I2S_TEST_SKIP_SAMPLERATE_88200);

	i2s_dir_both_transfer_short(88200);
}

/** @brief Short I2S transfer using I2S_DIR_BOTH and sample rate of 96000.
 *
 * - START trigger starts both the transmission and reception.
 * - Sending / receiving a short sequence of data returns success.
 * - DRAIN trigger empties the transmit queue and stops both streams.
 */
ZTEST(drivers_i2s_speed_both_rxtx, test_i2s_dir_both_transfer_short_96000)
{
	Z_TEST_SKIP_IFDEF(CONFIG_I2S_TEST_SKIP_SAMPLERATE_96000);

	i2s_dir_both_transfer_short(96000);
}

/** @brief Long I2S transfer using I2S_DIR_BOTH.
 *
 * - START trigger starts both the transmission and reception.
 * - Sending / receiving a long sequence of data returns success.
 * - DRAIN trigger empties the transmit queue and stops both streams.
 */
ZTEST(drivers_i2s_speed_both_rxtx, test_i2s_dir_both_transfer_long_44100)
{
	if (!dir_both_supported) {
		TC_PRINT("I2S_DIR_BOTH value is not supported.\n");
		ztest_test_skip();
		return;
	}

	void *rx_block[NUM_BLOCKS];
	void *tx_block[NUM_BLOCKS];
	size_t rx_size;
	int tx_idx;
	int rx_idx = 0;
	int num_verified;
	int ret;
	uint32_t frame_clk_freq = 44100;

	/* Configure I2S Dir Both transfer. */
	ret = configure_stream(dev_i2s_rxtx, I2S_DIR_BOTH, frame_clk_freq);
	zassert_equal(ret, TC_PASS);

	/* Prepare TX data blocks */
	for (tx_idx = 0; tx_idx < NUM_BLOCKS; tx_idx++) {
		ret = k_mem_slab_alloc(&tx_0_mem_slab, &tx_block[tx_idx],
				       K_FOREVER);
		zassert_equal(ret, 0);
		fill_buf((uint16_t *)tx_block[tx_idx], tx_idx % 3);
	}

	tx_idx = 0;

	/* Prefill TX queue */
	ret = i2s_write(dev_i2s_rxtx, tx_block[tx_idx++], BLOCK_SIZE);
	zassert_equal(ret, 0);

	ret = i2s_write(dev_i2s_rxtx, tx_block[tx_idx++], BLOCK_SIZE);
	zassert_equal(ret, 0);

	ret = i2s_trigger(dev_i2s_rxtx, I2S_DIR_BOTH, I2S_TRIGGER_START);
	zassert_equal(ret, 0, "RX/TX START trigger failed\n");

	for (; tx_idx < NUM_BLOCKS; ) {
		ret = i2s_write(dev_i2s_rxtx, tx_block[tx_idx++], BLOCK_SIZE);
		zassert_equal(ret, 0);

		ret = i2s_read(dev_i2s_rxtx, &rx_block[rx_idx++], &rx_size);
		zassert_equal(ret, 0);
		zassert_equal(rx_size, BLOCK_SIZE);
	}

	/* All data written, drain TX queue and stop both streams. */
	ret = i2s_trigger(dev_i2s_rxtx, I2S_DIR_BOTH, I2S_TRIGGER_DRAIN);
	zassert_equal(ret, 0, "RX/TX DRAIN trigger failed");

	ret = i2s_read(dev_i2s_rxtx, &rx_block[rx_idx++], &rx_size);
	zassert_equal(ret, 0);
	zassert_equal(rx_size, BLOCK_SIZE);

	ret = i2s_read(dev_i2s_rxtx, &rx_block[rx_idx++], &rx_size);
	zassert_equal(ret, 0);
	zassert_equal(rx_size, BLOCK_SIZE);

	TC_PRINT("%d TX blocks sent\n", tx_idx);
	TC_PRINT("%d RX blocks received\n", rx_idx);

	/* Verify received data */
	num_verified = 0;
	for (rx_idx = 0; rx_idx < NUM_BLOCKS; rx_idx++) {
		ret = verify_buf((uint16_t *)rx_block[rx_idx], rx_idx % 3);
		if (ret != 0) {
			TC_PRINT("%d RX block invalid\n", rx_idx);
		} else {
			num_verified++;
		}
		k_mem_slab_free(&rx_0_mem_slab, rx_block[rx_idx]);
	}
	zassert_equal(num_verified, NUM_BLOCKS, "Invalid RX blocks received");
}

static void *test_i2s_speed_configure(void)
{
	/* Check if I2S TX and I2S RX devices are ready. */
	dev_i2s_tx = DEVICE_DT_GET_OR_NULL(I2S_DEV_NODE_TX);
	zassert_not_null(dev_i2s_tx, "transfer device not found");
	zassert(device_is_ready(dev_i2s_tx), "transfer device not ready");

	dev_i2s_rx = DEVICE_DT_GET_OR_NULL(I2S_DEV_NODE_RX);
	zassert_not_null(dev_i2s_rx, "receive device not found");
	zassert(device_is_ready(dev_i2s_rx), "receive device not ready");

	return 0;
}

static void *test_i2s_speed_rxtx_configure(void)
{
	int ret;

	/* Configure I2S Dir Both transfer. */
	dev_i2s_rxtx = DEVICE_DT_GET_OR_NULL(I2S_DEV_NODE_RX);
	zassert_not_null(dev_i2s_rxtx, "receive device not found");
	zassert(device_is_ready(dev_i2s_rxtx), "receive device not ready");

	ret = configure_stream(dev_i2s_rxtx, I2S_DIR_BOTH, 44100);
	zassert_equal(ret, TC_PASS);

	/* Check if the tested driver supports the I2S_DIR_BOTH value.
	 * Use the DROP trigger for this, as in the current state of the driver
	 * (READY, both TX and RX queues empty) it is actually a no-op.
	 */
	ret = i2s_trigger(dev_i2s_rxtx, I2S_DIR_BOTH, I2S_TRIGGER_DROP);
	dir_both_supported = (ret == 0);

	if (IS_ENABLED(CONFIG_I2S_TEST_USE_I2S_DIR_BOTH)) {
		zassert_true(dir_both_supported,
			     "I2S_DIR_BOTH value is supposed to be supported.");
	}

	return 0;
}


ZTEST_SUITE(drivers_i2s_speed, NULL, test_i2s_speed_configure, NULL, NULL, NULL);
ZTEST_SUITE(drivers_i2s_speed_both_rxtx, NULL, test_i2s_speed_rxtx_configure, NULL, NULL, NULL);
```
